# AVR32SD28 register map
Vendor: Atmel; File version: 1.0
CPU: other r0p0, little endian, no MPU, no FPU, 4 interrupt priority bits
Registers are 8-bit, read-write, reset 0x0 unless marked. A register's access mark holds for its fields unless they carry their own. Offsets are from the block's base; [hi:lo] are bit positions.

## PORTMUX — Port Multiplexer
Base 0x008005E0
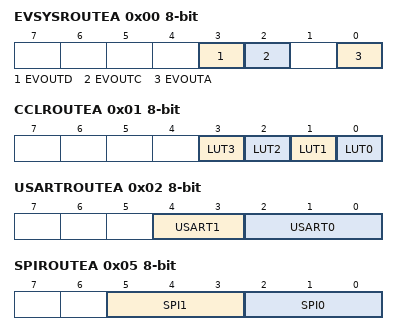
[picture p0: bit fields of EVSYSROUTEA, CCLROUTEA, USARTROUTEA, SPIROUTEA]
0x00 EVSYSROUTEA
  [3] EVOUTD — Event Output D
    0=DEFAULT (EVOUT on PD2); 1=ALT1 (EVOUT on PD7)
  [2] EVOUTC — Event Output C
    0=DEFAULT (EVOUT on PC2)
  [0] EVOUTA — Event Output A
    0=DEFAULT (EVOUT on PA2); 1=ALT1 (EVOUT on PA7)
0x01 CCLROUTEA
  [3] LUT3 — CCL Look-Up Table 3 Signals
    0=DEFAULT (Out: N/A In: PF0, PF1, -)
  [2] LUT2 — CCL Look-Up Table 2 Signals
    0=DEFAULT (Out: PD3 In: -, PD1, PD2); 1=ALT1 (Out: PD6 In: -, PD1, PD2)
  [1] LUT1 — CCL Look-Up Table 1 Signals
    0=DEFAULT (Out: PC3 In: PC0, PC1, PC2); 1=ALT1 (Out: - In: PC0, PC1, PC2)
  [0] LUT0 — CCL Look-Up Table 0 Signals
    0=DEFAULT (Out: PA3 In: PA0, PA1, PA2); 1=ALT1 (Out: PA6 In: PA0, PA1, PA2)
0x02 USARTROUTEA
  [4:3] USART1 — USART1 Signals
    0=DEFAULT (PC0, PC1, PC2, PC3); 2=ALT2 (PD6, PD7); 3=NONE (Not connected to any pins)
  [2:0] USART0 — USART0 Signals
    0=DEFAULT (PA0, PA1, PA2, PA3); 1=ALT1 (PA4, PA5, PA6, PA7); 2=ALT2 (PA2, PA3); 3=ALT3 (PD4, PD5, PD6, PD7); 4=ALT4 (PC1, PC2, PC3); 5=NONE (Not connected to any pins)
0x03 USARTROUTEB
  [1:0] USART2 — USART2 Signals
    0=DEFAULT (PF0, PF1, -, -); 3=NONE (Not connected to any pins)
0x05 SPIROUTEA
  [5:3] SPI1 — SPI1 Signals
    0=DEFAULT (PC0, PC1, PC2, PC3); 7=NONE (MOSI, MISO, SCK: N/A. SS Set to 1)
  [2:0] SPI0 — SPI0 Signals
    0=DEFAULT (PA4, PA5, PA6, PA7); 3=ALT3 (PA0, PA1, PC0, PC1); 4=ALT4 (PD4, PD5, PD6, PD7); 5=ALT5 (PC0, PC1, PC2, PC3); 6=ALT6 (PC1, PC2, PC3. SS Set to 1); 7=NONE (MOSI, MISO, SCK: N/A. SS Set to 1)
0x06 TWIROUTEA
  [1:0] TWI0 — TWI0 Signals
    0=DEFAULT (PA2, PA3, PC2, PC3); 1=ALT1 (PA2, PA3, -, -); 2=ALT2 (PC2, PC3, -, -); 3=ALT3 (PA0, PA1, PC2, PC3)
0x07 TCAROUTEA
  [2:0] TCA0 — TCA0 Signals
    0=PORTA (PA0, PA1, PA2, PA3, PA4, PA5); 2=PORTC (PC0, PC1, PC2, PC3, -, -); 3=PORTD (-, PD1, PD2, PD3, PD4, PD5); 5=PORTF (PF0, PF1, -, -, -, -)
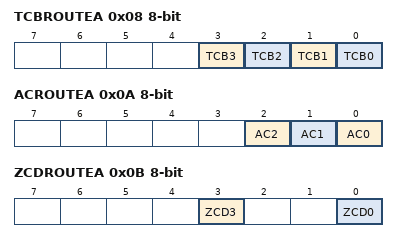
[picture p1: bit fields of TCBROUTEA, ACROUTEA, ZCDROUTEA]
0x08 TCBROUTEA
  [3] TCB3 — TCB3 Output
    0=DEFAULT (Not connected to any pins); 1=ALT1 (WO on PC1)
  [2] TCB2 — TCB2 Output
    0=DEFAULT (WO on PC0)
  [1] TCB1 — TCB1 Output
    0=DEFAULT (WO on PA3)
  [0] TCB0 — TCB0 Output
    0=DEFAULT (WO on PA2)
0x09 TCDROUTEA
  [2:0] TCD0 — TCD0 Signals
    0=DEFAULT (PA4, PA5, PA6, PA7); 2=ALT2 (PF0, PF1, -, -); 4=ALT4 (PA4, PA5, PD4, PD5)
0x0A ACROUTEA
  [all] fields
    0=DEFAULT (OUT on PA7)
  [2] AC2 — Analog Comparator 2 Output
  [1] AC1 — Analog Comparator 1 Output
  [0] AC0 — Analog Comparator 0 Output
0x0B ZCDROUTEA
  [3] ZCD3 — Zero Cross Detector 3 Output
    0=DEFAULT (OUT on PA7)
  [0] ZCD0 — Zero Cross Detector 0 Output
    0=DEFAULT (OUT on PA7)
0x0D ERRCTRLROUTEA — Error Controller Route A
  [2:0] HEART — Error Controller Heartbeat Output
    0=DEFAULT (HEART on PA2); 1=ALT1 (HEART on PA4); 2=ALT2 (HEART on PA6); 3=ALT3 (HEART on PA7); 4=ALT4 (HEART on PD4)

## RAMCTRL — RAM Controller
Base 0x00800E30
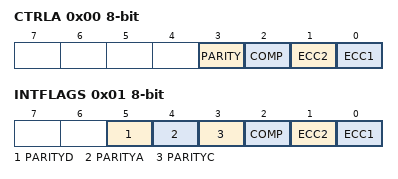
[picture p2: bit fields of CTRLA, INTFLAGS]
0x00 CTRLA — Control A
  [3] PARITY — Inject Parity Error
  [2] COMP — Inject ECC Compare Error
  [1] ECC2 — Inject 2-bit ECC Error
  [0] ECC1 — Inject 1-bit ECC Error
0x01 INTFLAGS — Interrupt Flags
  [5] PARITYD — Parity Error Detected on Write Data
  [4] PARITYA — Parity Error Detected on Address
  [3] PARITYC — Parity Error Detected on Control
  [2] COMP — Comparator Mismatch Error Detected
  [1] ECC2 — ECC Multibit Error Detected
  [0] ECC1 — ECC 1-bit Error Detected
0x02 ADDR 16-bit ro (reset mask 0xFF) — ECC Address
0x04 SYNDROME ro — ECC Syndrome

## RSTCTRL — Reset controller
Base 0x00800040
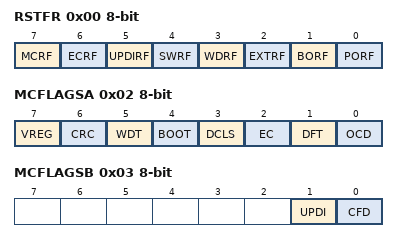
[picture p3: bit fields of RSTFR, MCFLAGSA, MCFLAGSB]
0x00 RSTFR — Reset Flags
  [7] MCRF — Machine Check Reset Flag
  [6] ECRF — Error Controller Reset Flag
  [5] UPDIRF — UPDI Reset Flag
  [4] SWRF — Software Reset Flag
  [3] WDRF — Watchdog Reset Flag
  [2] EXTRF — External Reset Flag
  [1] BORF — Brown-out Detector Reset Flag
  [0] PORF — Power-On Reset Flag
0x01 SWRR — Software Reset
  [0] SWRST
0x02 MCFLAGSA — Machine Check Flags A
  [7] VREG — Voltage Regulator Monitor
  [6] CRC — CRC Scan Error
  [5] WDT — WDT Clock Failure Monitor
  [4] BOOT — Boot Error Detected
  [3] DCLS — Dual Core Lockstep Comparator Mismatch
  [2] EC — Error Controller Internal Error
  [1] DFT — Design-for-Test Mechanism Enabled
  [0] OCD — OCD System Enabled
0x03 MCFLAGSB — Machine Check Flags B
  [1] UPDI — Illegal UPDI bus activity detected
  [0] CFD — Clock Failure Detect
